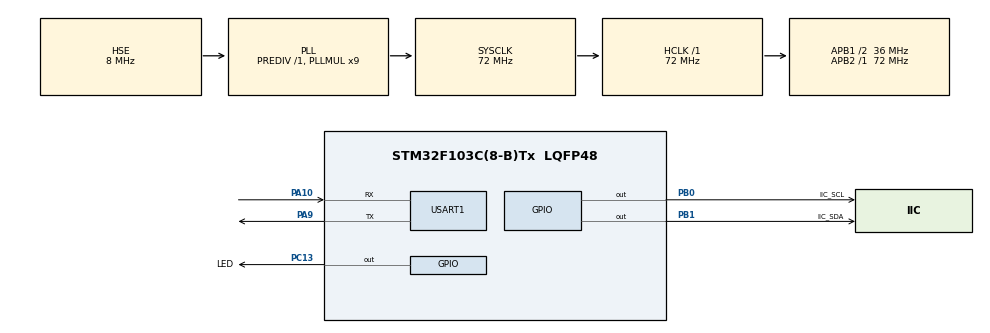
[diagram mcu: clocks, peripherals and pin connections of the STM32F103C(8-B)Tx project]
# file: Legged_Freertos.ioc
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FREERTOS.Tasks01=defaultTask,0,128,StartDefaultTask,Default,NULL,Dynamic,NULL,NULL;LEDTask,-3,128,StartLedTask,Default,NULL,Dynamic,NULL,NULL
Mcu.Family=STM32F1
Mcu.Name=STM32F103C(8-B)Tx
Mcu.Package=LQFP48
NVIC.PriorityGroup=NVIC_PRIORITYGROUP_4
NVIC.TIM1_UP_IRQn=true\:0\:0\:false\:false\:true\:false\:false\:true
NVIC.TIM2_IRQn=true\:1\:0\:true\:false\:true\:false\:true\:true
NVIC.TimeBase=TIM1_UP_IRQn
NVIC.TimeBaseIP=TIM1
NVIC.USART1_IRQn=true\:3\:0\:true\:false\:true\:false\:true\:true
PA10.Mode=Asynchronous
PA10.Signal=USART1_RX
PA13.Mode=Serial_Wire
PA13.Signal=SYS_JTMS-SWDIO
PA14.Mode=Serial_Wire
PA14.Signal=SYS_JTCK-SWCLK
PA9.Mode=Asynchronous
PA9.Signal=USART1_TX
PB0.GPIO_Label=IIC_SCL
PB0.GPIO_Speed=GPIO_SPEED_FREQ_HIGH
PB0.Signal=GPIO_Output
PB1.GPIO_Label=IIC_SDA
PB1.GPIO_Speed=GPIO_SPEED_FREQ_HIGH
PB1.Signal=GPIO_Output
PC13-TAMPER-RTC.GPIO_Label=LED
PC13-TAMPER-RTC.Signal=GPIO_Output
PC14-OSC32_IN.Mode=LSE-External-Oscillator
PC14-OSC32_IN.Signal=RCC_OSC32_IN
PC15-OSC32_OUT.Mode=LSE-External-Oscillator
PC15-OSC32_OUT.Signal=RCC_OSC32_OUT
PD0-OSC_IN.Mode=HSE-External-Oscillator
PD0-OSC_IN.Signal=RCC_OSC_IN
PD1-OSC_OUT.Mode=HSE-External-Oscillator
PD1-OSC_OUT.Signal=RCC_OSC_OUT
ProjectManager.HeapSize=0x200
ProjectManager.StackSize=0x400
ProjectManager.TargetToolchain=MDK-ARM V5
RCC.AHBFreq_Value=72000000
RCC.APB1CLKDivider=RCC_HCLK_DIV2
RCC.APB1Freq_Value=36000000
RCC.APB1TimFreq_Value=72000000
RCC.APB2Freq_Value=72000000
RCC.APB2TimFreq_Value=72000000
RCC.HCLKFreq_Value=72000000
RCC.PLLMUL=RCC_PLL_MUL9
RCC.PLLSourceVirtual=RCC_PLLSOURCE_HSE
RCC.SYSCLKFreq_VALUE=72000000
RCC.SYSCLKSource=RCC_SYSCLKSOURCE_PLLCLK
RCC.USBFreq_Value=72000000
TIM2.Period=1000
TIM2.Prescaler=71
USART1.VirtualMode=VM_ASYNC
VP_FREERTOS_VS_CMSIS_V1.Mode=CMSIS_V1
VP_SYS_VS_tim1.Mode=TIM1
VP_TIM2_VS_ClockSourceINT.Mode=Internal
board=custom

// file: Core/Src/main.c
/* USER CODE BEGIN Header */
/**
  ******************************************************************************
  * @file           : main.c
  * @brief          : Main program body
  ******************************************************************************
  * @attention
  *
  * <h2><center>&copy; Copyright (c) 2020 STMicroelectronics.
  * All rights reserved.</center></h2>
  *
  * This software component is licensed by ST under Ultimate Liberty license
  * SLA0044, the "License"; You may not use this file except in compliance with
  * the License. You may obtain a copy of the License at:
  *                             www.st.com/SLA0044
  *
  ******************************************************************************
  */
/* USER CODE END Header */
#include "main.h"
#include "cmsis_os.h"
#include "tim.h"
#include "usart.h"
#include "gpio.h"

/* USER CODE BEGIN PV */
extern uint8_t ControlBuffer;			//接收中断缓冲
/* USER CODE END PV */

void SystemClock_Config(void);
void MX_FREERTOS_Init(void);

int main(void)
{

  /* MCU Configuration--------------------------------------------------------*/

  /* Reset of all peripherals, Initializes the Flash interface and the Systick. */

  HAL_Init();

  /* Configure the system clock */
  SystemClock_Config();

  /* Initialize all configured peripherals */
  MX_GPIO_Init();
  MX_TIM2_Init();
  MX_USART1_UART_Init();
  /* USER CODE BEGIN 2 */
	printf("串口传输START\r\n");
	/* 用户硬件初始化 */
	PCA9685_Init(50);
	/* 开启定时器2 */
	HAL_TIM_Base_Start_IT(&htim2);
	HAL_UART_Receive_IT(&huart1, (uint8_t *)&ControlBuffer, 1);
  /* USER CODE END 2 */

  /* Call init function for freertos objects (in freertos.c) */
  MX_FREERTOS_Init();
  /* Start scheduler */
  osKernelStart();

  /* We should never get here as control is now taken by the scheduler */
  /* Infinite loop */
  while (1)
  {

  }
}

void SystemClock_Config(void)
{
  RCC_OscInitTypeDef RCC_OscInitStruct = {0};
  RCC_ClkInitTypeDef RCC_ClkInitStruct = {0};

  /** Initializes the RCC Oscillators according to the specified parameters
  * in the RCC_OscInitTypeDef structure.
  */
  RCC_OscInitStruct.OscillatorType = RCC_OSCILLATORTYPE_HSE;
  RCC_OscInitStruct.HSEState = RCC_HSE_ON;
  RCC_OscInitStruct.HSEPredivValue = RCC_HSE_PREDIV_DIV1;
  RCC_OscInitStruct.HSIState = RCC_HSI_ON;
  RCC_OscInitStruct.PLL.PLLState = RCC_PLL_ON;
  RCC_OscInitStruct.PLL.PLLSource = RCC_PLLSOURCE_HSE;
  RCC_OscInitStruct.PLL.PLLMUL = RCC_PLL_MUL9;
  if (HAL_RCC_OscConfig(&RCC_OscInitStruct) != HAL_OK)
  {
    Error_Handler();
  }
  /** Initializes the CPU, AHB and APB buses clocks
  */
  RCC_ClkInitStruct.ClockType = RCC_CLOCKTYPE_HCLK|RCC_CLOCKTYPE_SYSCLK
                              |RCC_CLOCKTYPE_PCLK1|RCC_CLOCKTYPE_PCLK2;
  RCC_ClkInitStruct.SYSCLKSource = RCC_SYSCLKSOURCE_PLLCLK;
  RCC_ClkInitStruct.AHBCLKDivider = RCC_SYSCLK_DIV1;
  RCC_ClkInitStruct.APB1CLKDivider = RCC_HCLK_DIV2;
  RCC_ClkInitStruct.APB2CLKDivider = RCC_HCLK_DIV1;

  if (HAL_RCC_ClockConfig(&RCC_ClkInitStruct, FLASH_LATENCY_2) != HAL_OK)
  {
    Error_Handler();
  }
}

void HAL_TIM_PeriodElapsedCallback(TIM_HandleTypeDef *htim)
{
  if (htim->Instance == TIM1) {
    HAL_IncTick();
  }
  /* USER CODE BEGIN Callback 1 */
  if (htim == (&htim2))
  {
		Clock_Time();
  }
  /* USER CODE END Callback 1 */
}

void Error_Handler(void)
{
}

/************************ (C) COPYRIGHT STMicroelectronics *****END OF FILE****/

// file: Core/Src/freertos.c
/* USER CODE BEGIN Header */
/**
  ******************************************************************************
  * File Name          : freertos.c
  * Description        : Code for freertos applications
  ******************************************************************************
  * @attention
  *
  * <h2><center>&copy; Copyright (c) 2020 STMicroelectronics.
  * All rights reserved.</center></h2>
  *
  * This software component is licensed by ST under Ultimate Liberty license
  * SLA0044, the "License"; You may not use this file except in compliance with
  * the License. You may obtain a copy of the License at:
  *                             www.st.com/SLA0044
  *
  ******************************************************************************
  */
/* USER CODE END Header */

#include "FreeRTOS.h"
#include "task.h"
#include "main.h"
#include "cmsis_os.h"

/* USER CODE BEGIN Includes */
#include "start_task.h"
/* USER CODE END Includes */

osThreadId defaultTaskHandle;

void StartDefaultTask(void const * argument);
void StartLedTask(void const * argument);

void MX_FREERTOS_Init(void); /* (MISRA C 2004 rule 8.1) */

/* GetIdleTaskMemory prototype (linked to static allocation support) */
void vApplicationGetIdleTaskMemory( StaticTask_t **ppxIdleTaskTCBBuffer, StackType_t **ppxIdleTaskStackBuffer, uint32_t *pulIdleTaskStackSize );

/* USER CODE BEGIN GET_IDLE_TASK_MEMORY */
static StaticTask_t xIdleTaskTCBBuffer;
static StackType_t xIdleStack[configMINIMAL_STACK_SIZE];

void vApplicationGetIdleTaskMemory( StaticTask_t **ppxIdleTaskTCBBuffer, StackType_t **ppxIdleTaskStackBuffer, uint32_t *pulIdleTaskStackSize )
{
  *ppxIdleTaskTCBBuffer = &xIdleTaskTCBBuffer;
  *ppxIdleTaskStackBuffer = &xIdleStack[0];
  *pulIdleTaskStackSize = configMINIMAL_STACK_SIZE;
  /* place for user code */
}
/* USER CODE END GET_IDLE_TASK_MEMORY */

void MX_FREERTOS_Init(void) {

  /* Create the thread(s) */
  /* definition and creation of defaultTask */
  osThreadDef(defaultTask, StartDefaultTask, osPriorityIdle, 0, 30);
  defaultTaskHandle = osThreadCreate(osThread(defaultTask), NULL);

  /* USER CODE BEGIN RTOS_THREADS */
	StartTest();
  /* add threads, ... */
  /* USER CODE END RTOS_THREADS */

}

void StartDefaultTask(void const * argument)
{
  /* USER CODE BEGIN StartDefaultTask */
  /* Infinite loop */
  for(;;)
  {
		LED_TOGGLE;
    osDelay(100);
  }
  /* USER CODE END StartDefaultTask */
}

/************************ (C) COPYRIGHT STMicroelectronics *****END OF FILE****/
